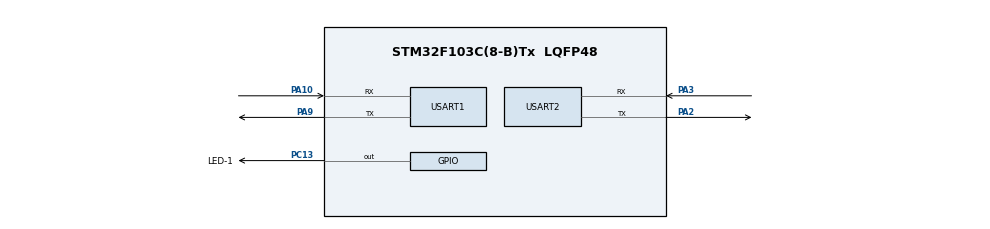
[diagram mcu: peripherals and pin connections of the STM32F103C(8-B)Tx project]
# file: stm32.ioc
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Mcu.Family=STM32F1
Mcu.Name=STM32F103C(8-B)Tx
Mcu.Package=LQFP48
NVIC.PriorityGroup=NVIC_PRIORITYGROUP_4
NVIC.USART1_IRQn=true\:0\:0\:false\:false\:true\:true\:true\:true
NVIC.USART2_IRQn=true\:0\:0\:false\:false\:true\:true\:true\:true
PA10.Mode=Asynchronous
PA10.Signal=USART1_RX
PA13.Mode=Serial_Wire
PA13.Signal=SYS_JTMS-SWDIO
PA14.Mode=Serial_Wire
PA14.Signal=SYS_JTCK-SWCLK
PA2.Mode=Asynchronous
PA2.Signal=USART2_TX
PA3.Mode=Asynchronous
PA3.Signal=USART2_RX
PA9.Mode=Asynchronous
PA9.Signal=USART1_TX
PC13-TAMPER-RTC.GPIO_Label=LED-1
PC13-TAMPER-RTC.GPIO_Speed=GPIO_SPEED_FREQ_HIGH
PC13-TAMPER-RTC.PinState=GPIO_PIN_SET
PC13-TAMPER-RTC.Signal=GPIO_Output
ProjectManager.HeapSize=0x200
ProjectManager.StackSize=0x400
ProjectManager.TargetToolchain=STM32CubeIDE
RCC.APB1Freq_Value=8000000
RCC.APB2Freq_Value=8000000
USART1.VirtualMode=VM_ASYNC
USART2.VirtualMode=VM_ASYNC
board=custom

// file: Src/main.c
/* USER CODE BEGIN Header */
/**
  ******************************************************************************
  * @file           : main.c
  * @brief          : Main program body
  ******************************************************************************
  * @attention
  *
  * Copyright (c) 2023 STMicroelectronics.
  * All rights reserved.
  *
  * This software is licensed under terms that can be found in the LICENSE file
  * in the root directory of this software component.
  * If no LICENSE file comes with this software, it is provided AS-IS.
  *
  ******************************************************************************
  */
/* USER CODE END Header */
#include "main.h"
#include <stdio.h>
#include <inttypes.h>

UART_HandleTypeDef huart1;
UART_HandleTypeDef huart2;

void SystemClock_Config(void);
static void MX_GPIO_Init(void);
static void MX_USART2_UART_Init(void);
static void MX_USART1_UART_Init(void);

/* USER CODE BEGIN 0 */
static  uint8_t tx_buff[1024];
/* USER CODE END 0 */

int main(void)
{

  /* MCU Configuration--------------------------------------------------------*/

  /* Reset of all peripherals, Initializes the Flash interface and the Systick. */
  HAL_Init();

  /* Configure the system clock */
  SystemClock_Config();

  /* Initialize all configured peripherals */
  MX_GPIO_Init();
  MX_USART2_UART_Init();
  MX_USART1_UART_Init();

  /* Infinite loop */
  while (1)
  {
      //struct timeval systemTime;
      //gettimeofday(&systemTime,NULL);
      //return (int64_t)systemTime.tv_sec * 1000LL + (int64_t)systemTime.tv_usec/1000;
      snprintf(tx_buff,sizeof (tx_buff),"%s %zu %" PRId64 "\r\n","Stm32 Hello World",HAL_GetTick(),((int64_t)1234123));
      HAL_UART_Transmit_IT(&huart2, tx_buff, sizeof(tx_buff));

      HAL_GPIO_TogglePin(LED_1_GPIO_Port,LED_1_Pin);
      HAL_Delay(40);
  }
}

void SystemClock_Config(void)
{
  RCC_OscInitTypeDef RCC_OscInitStruct = {0};
  RCC_ClkInitTypeDef RCC_ClkInitStruct = {0};

  /** Initializes the RCC Oscillators according to the specified parameters
  * in the RCC_OscInitTypeDef structure.
  */
  RCC_OscInitStruct.OscillatorType = RCC_OSCILLATORTYPE_HSI;
  RCC_OscInitStruct.HSIState = RCC_HSI_ON;
  RCC_OscInitStruct.HSICalibrationValue = RCC_HSICALIBRATION_DEFAULT;
  RCC_OscInitStruct.PLL.PLLState = RCC_PLL_NONE;
  if (HAL_RCC_OscConfig(&RCC_OscInitStruct) != HAL_OK)
  {
    Error_Handler();
  }

  /** Initializes the CPU, AHB and APB buses clocks
  */
  RCC_ClkInitStruct.ClockType = RCC_CLOCKTYPE_HCLK|RCC_CLOCKTYPE_SYSCLK
                              |RCC_CLOCKTYPE_PCLK1|RCC_CLOCKTYPE_PCLK2;
  RCC_ClkInitStruct.SYSCLKSource = RCC_SYSCLKSOURCE_HSI;
  RCC_ClkInitStruct.AHBCLKDivider = RCC_SYSCLK_DIV1;
  RCC_ClkInitStruct.APB1CLKDivider = RCC_HCLK_DIV1;
  RCC_ClkInitStruct.APB2CLKDivider = RCC_HCLK_DIV1;

  if (HAL_RCC_ClockConfig(&RCC_ClkInitStruct, FLASH_LATENCY_0) != HAL_OK)
  {
    Error_Handler();
  }
}

static void MX_USART1_UART_Init(void)
{

  huart1.Instance = USART1;
  huart1.Init.BaudRate = 115200;
  huart1.Init.WordLength = UART_WORDLENGTH_8B;
  huart1.Init.StopBits = UART_STOPBITS_1;
  huart1.Init.Parity = UART_PARITY_NONE;
  huart1.Init.Mode = UART_MODE_TX_RX;
  huart1.Init.HwFlowCtl = UART_HWCONTROL_NONE;
  huart1.Init.OverSampling = UART_OVERSAMPLING_16;
  if (HAL_UART_Init(&huart1) != HAL_OK)
  {
    Error_Handler();
  }

}

static void MX_USART2_UART_Init(void)
{

  huart2.Instance = USART2;
  huart2.Init.BaudRate = 115200;
  huart2.Init.WordLength = UART_WORDLENGTH_8B;
  huart2.Init.StopBits = UART_STOPBITS_1;
  huart2.Init.Parity = UART_PARITY_NONE;
  huart2.Init.Mode = UART_MODE_TX_RX;
  huart2.Init.HwFlowCtl = UART_HWCONTROL_NONE;
  huart2.Init.OverSampling = UART_OVERSAMPLING_16;
  if (HAL_UART_Init(&huart2) != HAL_OK)
  {
    Error_Handler();
  }

}

static void MX_GPIO_Init(void)
{
  GPIO_InitTypeDef GPIO_InitStruct = {0};

  /* GPIO Ports Clock Enable */
  __HAL_RCC_GPIOC_CLK_ENABLE();
  __HAL_RCC_GPIOA_CLK_ENABLE();

  /*Configure GPIO pin Output Level */
  HAL_GPIO_WritePin(LED_1_GPIO_Port, LED_1_Pin, GPIO_PIN_SET);

  /*Configure GPIO pin : LED_1_Pin */
  GPIO_InitStruct.Pin = LED_1_Pin;
  GPIO_InitStruct.Mode = GPIO_MODE_OUTPUT_PP;
  GPIO_InitStruct.Pull = GPIO_NOPULL;
  GPIO_InitStruct.Speed = GPIO_SPEED_FREQ_HIGH;
  HAL_GPIO_Init(LED_1_GPIO_Port, &GPIO_InitStruct);

}

void Error_Handler(void)
{
  __disable_irq();
  while (1)
  {
  }
}
